# SF32LB56x register map
File version: 1.0
CPU: CM33 r0p1, little endian, MPU, FPU, 3 interrupt priority bits
Registers are 32-bit, read-write, reset 0x0 unless marked. A register's access mark holds for its fields unless they carry their own. Offsets are from the block's base; [hi:lo] are bit positions.

## SCI
Base 0x4002D000
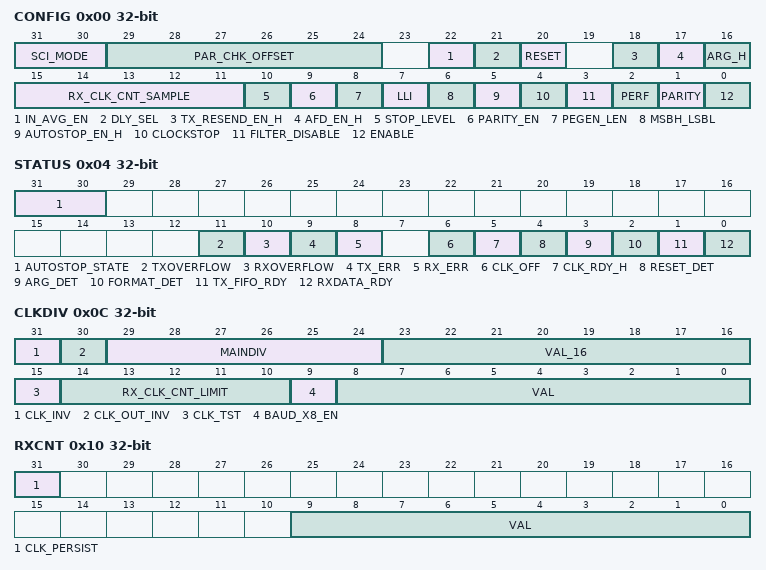
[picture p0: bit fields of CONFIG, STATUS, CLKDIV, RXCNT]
0x00 CONFIG
  [31:30] SCI_MODE — These bits are reserved and must be written as '00' for the SCI module to work properly: 2'b11: Ser In lt- Ser Out loopback 2'b10: Ser In lt- Ser In (unmasked) others = Ser In lt- Ser In masked with Txing_H (normal mode)
  [29:24] PAR_CHK_OFFSET — Allows fine control of the parity check position during the parity error time period
  [22] IN_AVG_EN — Input data average enable. 0: Disable 1: Enable
  [21] DLY_SEL — This selects between two delay times for the automatic clock stop startup and shutdown: 0: short delay Startup/Shutdown : 744 SCI clocks / 1860 SCI clocks 1: long delay Startup/Shutdown : (2 x 744) SCI clocks / (2 x 1860) SCI clocks
  [20] RESET — Direct connection to the SIM card reset pin. This is overridden when ARG_H is enabled 0: SCI_Reset low voltage 1: SCI Reset high voltage
  [18] TX_RESEND_EN_H — 1: Enable automatic resend of characters when Tx parity error is detected 0: Disable automatic resend
  [17] AFD_EN_H — Automatic format detection. This bit is generally set in conjunction with the ARG_H bit to enable automatic detection of the data convention. 1: Enable TS detection and automatic convention settings programming 0: disable automatic settings and use the register bits (MSBH_LSBL and LLI) to control the convention
  [16] ARG_H — Automatic Reset Generator. Write a '1' to this bit to initiate an automatic reset procedure on the SIM. Write '0' to switch back to SCI_Reset control (bit 20). An ARG interrupt will be generated if the ARG process succeeded or failed. The ARG status bit (ARG_Det) must be read to determine if a reset response from the card was detected. This bit needs to be cleared between ARG attempts
  [15:11] RX_CLK_CNT_SAMPLE — tunning the sample local
  [10] STOP_LEVEL — Logical value of the clock signal when SCI clock is stopped (either due to automatic shutdown or manual shutdown) 0: Stop clock at low level 1: Stop clock at high level
  [9] PARITY_EN — Enable or disable parity error checking on the receive data 0: Disable parity error checking 1: Enable parity error checking
  [8] PEGEN_LEN — Parity Error signal length. This configuration bit can be used to extend the duration of the parity error signal generation from 1 ETU to 1.5 ETU 0: Parity Error signal duration is 1 ETU starting at 10.5 ETU 1: Parity Error signal duration is 1.5 ETU starting at 10.5 ETU
  [7] LLI — Logic Level Invert 0: Logic level 0 data is sent/received as '0' or 'A' which is the same as the start bit. (direct convention) 1: logic level 0 data is sent/received as '1' or 'Z' which is the opposite of the start bit. (Inverse convention)
  [6] MSBH_LSBL — Sets the transmission and reception bit order: 0: LSB is sent/recieved first (Direct convention) 1: MSB is sent/received first (Inverse convention)
  [5] AUTOSTOP_EN_H — Enables automatic clock shutdown when command is complete. Enabling this will generate the necessary startup and shutdown delays required by the SIM protocol 0: Auto clock control not enabled. SCI clock controlled by SCI_Clockstop bit 1:Auto clock control enabled
  [4] CLOCKSTOP — Manual SCI Clock Stop control. Manually starts and stops the SCI clock. This bit must be set to '1' when Autostop mode is enabled 0: Enable the SCI clock 1: Disable SCI clock
  [3] FILTER_DISABLE — Enable or disable NULL(0x60) character filter when SIM card sends NULL to reset WWT timer 0: Enable NULL character filtering, nULL characters are not reported if not data 1: Disable NULL character filtering. NULL characters(0x60) are transferred to the SCIdata buffer
  [2] PERF — parity error receive feed-through 0: don't store bytes with detected parity errors 1: feed-through bytes with detected parity errors
  [1] PARITY — select the parity generation/detection 1: even parity 0: odd parity
  [0] ENABLE — enable the SIM Card IF module
0x04 STATUS
  [31:30] AUTOSTOP_STATE — Returns the state of the clock management state machine when AutoStop mode is enabled. This value is '00' when manual mode is selected 2'h0: Startup_phase - Clock is on, but not ready to be used 2'h1: Auto_on - Clock is on and ready to be used 2'h2: Shutdown_phase - Clock is still on, but should not be used 2'h3: Clock_off - Clock is off
  [11] TXOVERFLOW — The internal transmit FIFO has reached an overflow condition. Reading this register clears the bit
  [10] RXOVERFLOW — The internal receive FIFO has reached an overflow condition. Reading this register clears the bit
  [9] TX_ERR — A transmit parity error was detected. Reading this register clears the bit
  [8] RX_ERR — A receive parity error was detected. Reading this register clears the bit
  [6] CLK_OFF — Status bit of the Sci clock. 0: Sci clock is ON 1: Sci clock is OFF
  [5] CLK_RDY_H — Status of the control signal to the clock control module. This bit respects the startup and shutdown phases, so during these times, the clock may actually be on, but it is not considered to be 'ready' 0: SCI clock may be on or off but is not ready for use 1: SCI clock is on and ready for use
  [4] RESET_DET — This is the status of the Reset pin when automatic reset generation is enabled. This bit can be used to discover whether the SIM card that has successfully responded to an ARG procedure has an active high or active low reset. (Det means 'Detection')
  [3] ARG_DET — Returns the status of the automatic reset procedure: 0 = ARG detection has failed 1 = ARG detection has detected that the SIM has responded to the reset This bit is used in conjunction with the ARG interrupt. The ARG interrupt will be generated at the successful or unsuccessful termination of the ARG process. This bit can be used to determine the success or failure.
  [2] FORMAT_DET — Returns the status of the automatic format detection after reset: 0: TS character has not been detected in the ATR 1: TS character has been detected and SCI module is using the automatic convention settings This bit is cleared when the AFD_En bit is cleared
  [1] TX_FIFO_RDY — Returns the status of the Tx FIFO: 0: Tx FIFO is full 1: There is at least 1 free spot in the Tx FIFO
  [0] RXDATA_RDY — Returns the status of the Rx FIFO: 0: Rx FIFO empty 1: There is at least 1 character in the Rx FIFO
0x08 DATA
  [7:0] DATA_IO — Writing to this register will send the data to the SIM card. If automatic clock shutdown is enabled, the appropriate delay will be applied before the data is actually sent Reading this register will read from the receive data FIFO
0x0C CLKDIV
  [31] CLK_INV — Inverts SCI clock to the SIM card . 0: No inversion 1: Invert external SCI clock
  [30] CLK_OUT_INV — Inverts the polarity of the SCI clock to the SIM card only. 0: No inversion 1: Invert external SCI clock
  [29:24] MAINDIV — Main clock divider to generate the SCI clock. This value should be calculated as follows: MainDiv = Clk_Sys/(2xSCI_Clk) - 1 where SCI_Clk is in the range of 3-5 MHz as specified in the SIM specification.
  [23:16] VAL_16 — Secondary clock divider for generating 16x baud clock
  [15] CLK_TST
  [14:10] RX_CLK_CNT_LIMIT — Rx_clk_cnt wrap value
  [9] BAUD_X8_EN — Speed mode enable. 0: Low speed mode 1: High speed mode(372/32, 372/64, 512/64)
  [8:0] VAL — Clock divider for generating the baud clock from the SCI clock. This value must match the value used by the SIM card whose default value is 0x174
0x10 RXCNT
  [31] CLK_PERSIST — When in automatic clock shutdown mode, this bit can prevent the clock from entering shutdown mode when the transfer is complete. This should be used for multi-transfer commands where the clock must not be shut down until the command is complete. This bit must be programmed for each transfer. 1: Keep clock on 0: Allow clock shutdown when transfer is complete
  [9:0] VAL — This value should be programmed with the number of expected characters to receive. It will be decremented each time a character is actually received and should be 0 when the transfer is complete. If a character is sent after the RxCnt reaches zero, the extra character flag will be set but this value will stay at zero.
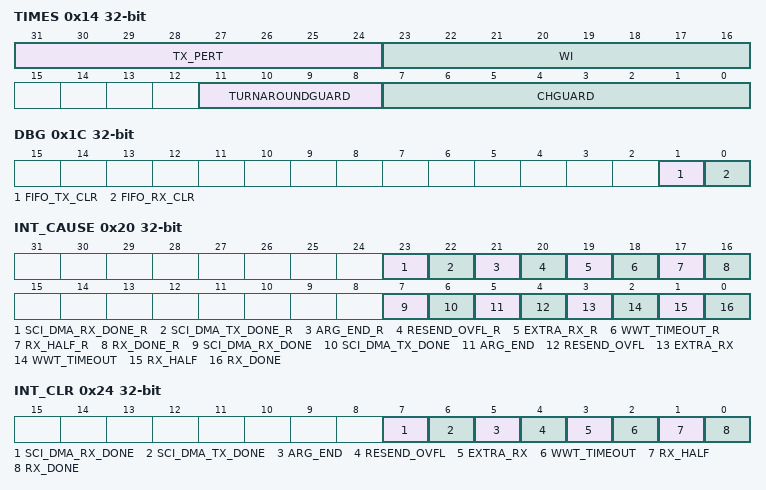
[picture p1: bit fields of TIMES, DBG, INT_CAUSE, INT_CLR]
0x14 TIMES
  [31:24] TX_PERT — Number of times to try resending character when the SIM indicates a parity error
  [23:16] WI — Work Waiting Time factor. A timeout will be generated when the WWT is exceeded. The WWT is calculated by: WWT = 960 x WI x (F/Fi) where Fi is the main SCI clock frequency (3-5 MHz) and F is 372 before an enhanced PPS and 512 after an enhanced PPS. The SCI_WI value must be calculated as follows: SCI_WI = WI * D Thus, by default (WI = 10) this value needs to be set to 10 before an EPPS, but needs to be scaled to WI*D=80 after the EPPS procedure. The WWT is disabled when the number of expected characters has been received. Extra characters will not cause a WWT interrupt.
  [11:8] TURNAROUNDGUARD — Turnaround guard time configuration. This value can be used to adjust the delay between the leading edge of a received character and the leading edge of the next transmitted character. The minimum time specified in the SIM recommendation is 16 ETU. The number of ETUs can be calculated using the following formula: Total Turnaround Time (in ETUs) = 11 + TurnaroundGuard
  [7:0] CHGUARD — This is the extra guard time that can be added to the 2 ETU minimum (and default) guard time between successive transmitted characters. This should be programmed depending on the SIM's ATR. The total ETU guard time will be ChGuard + 1.
0x18 CH_FILT
  [7:0] VAL — Value of the character to be filtered. 0x60 is the NULL character in the SIM protocol. If character filtering is enabled, the first 0x60 character that is received by the SIM during a transfer will not be recorded. The purpose of this character is to enable the SIM to reset the WWT counter when the SIM is not ready to send the data. This filter has no effect on characters within the datastream.
0x1C DBG
  [1] FIFO_TX_CLR — Clear TX FIFO
  [0] FIFO_RX_CLR — Clear RX FIFO
0x20 INT_CAUSE
  [23] SCI_DMA_RX_DONE_R — Not used
  [22] SCI_DMA_TX_DONE_R — Not used
  [21] ARG_END_R — Raw End of the ARG sequence. The status register must be read to determine whether the ARG sequence was successful or not
  [20] RESEND_OVFL_R — Raw The automatic re-transmit of parity error characters has exceeded the threshold specified in the Tx_PERT field
  [19] EXTRA_RX_R — Raw An extra character has been received after the number of characters in RxCnt has been received
  [18] WWT_TIMEOUT_R — Raw No Tx character has been sent NOR any Rx character detected within the WWT timeout
  [17] RX_HALF_R — Raw Receiver FIFO is half full
  [16] RX_DONE_R — Raw Number of expected Rx characters, as programmed in the RxCnt register, has been received.
  [7] SCI_DMA_RX_DONE — Not used
  [6] SCI_DMA_TX_DONE — Not used
  [5] ARG_END — End of the ARG sequence. The status register must be read to determine whether the ARG sequence was successful or not
  [4] RESEND_OVFL — The automatic re-transmit of parity error characters has exceeded the threshold specified in the Tx_PERT field
  [3] EXTRA_RX — An extra character has been received after the number of characters in RxCnt has been received
  [2] WWT_TIMEOUT — No Tx character has been sent NOR any Rx character detected within the WWT timeout
  [1] RX_HALF — Receiver FIFO is half full
  [0] RX_DONE — Number of expected Rx characters, as programmed in the RxCnt register, has been received.
0x24 INT_CLR
  [7] SCI_DMA_RX_DONE, [6] SCI_DMA_TX_DONE, [5] ARG_END, [4] RESEND_OVFL, [3] EXTRA_RX, [2] WWT_TIMEOUT, [1] RX_HALF, [0] RX_DONE
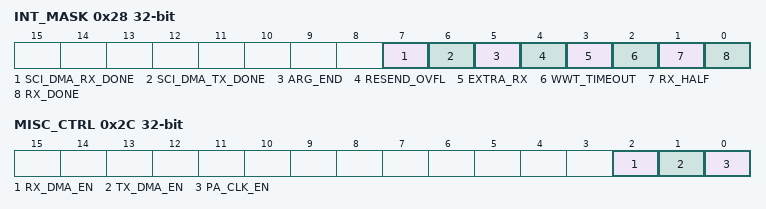
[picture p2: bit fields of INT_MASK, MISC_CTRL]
0x28 INT_MASK
  [7] SCI_DMA_RX_DONE — 0: mask the interrupt
  [6] SCI_DMA_TX_DONE — 0: mask the interrupt
  [5] ARG_END — 0: mask the interrupt
  [4] RESEND_OVFL — 0: mask the interrupt
  [3] EXTRA_RX — 0: mask the interrupt
  [2] WWT_TIMEOUT — 0: mask the interrupt
  [1] RX_HALF — 0: mask the interrupt
  [0] RX_DONE — 0: mask the interrupt
0x2C MISC_CTRL
  [2] RX_DMA_EN — rx dma enable
  [1] TX_DMA_EN — tx dma enable
  [0] PA_CLK_EN
0x30 PA_STATUS
  [0] ENABLE
